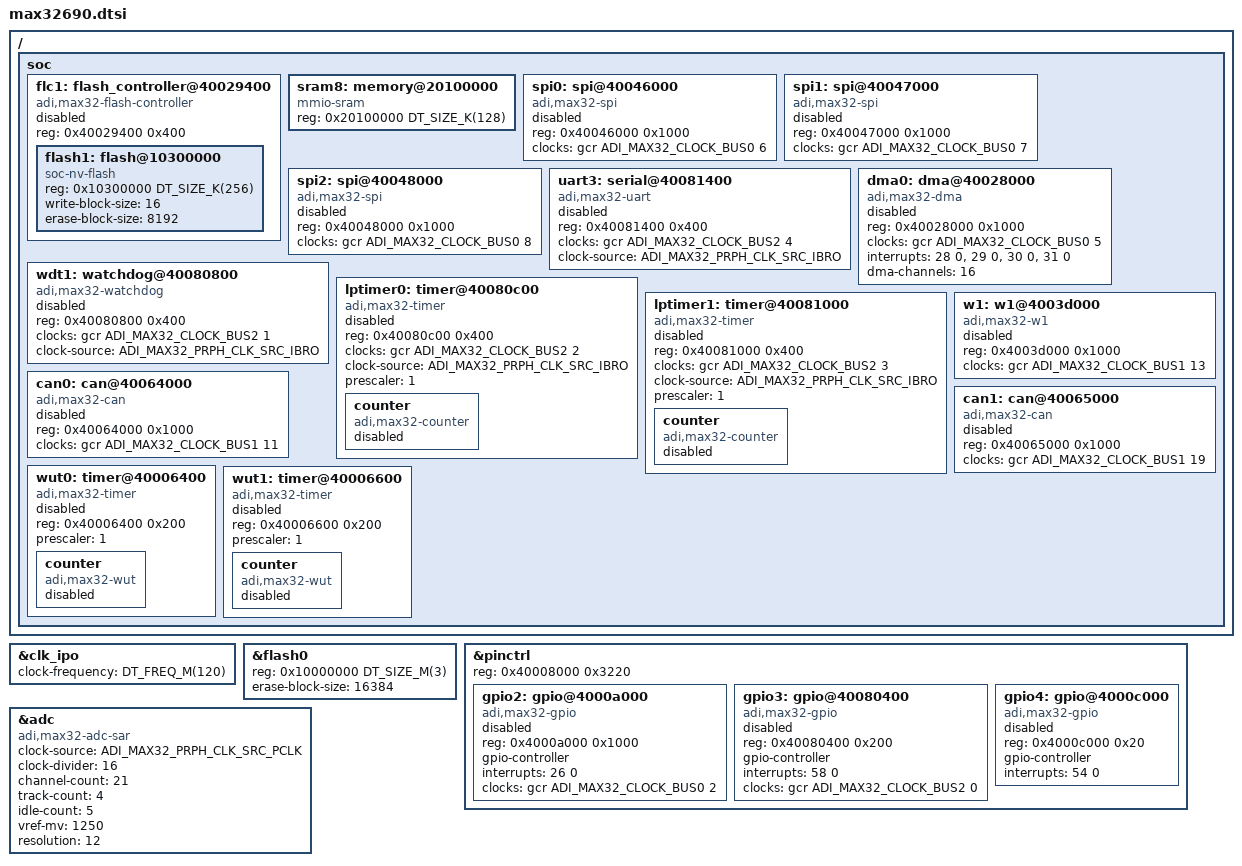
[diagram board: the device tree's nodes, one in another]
/*
 * Copyright (c) 2023-2025 Analog Devices, Inc.
 *
 * SPDX-License-Identifier: Apache-2.0
 */

#include <adi/max32/max32xxx.dtsi>
#include <zephyr/dt-bindings/dma/max32690_dma.h>

&clk_ipo {
	clock-frequency = <DT_FREQ_M(120)>;
};

&flash0 {
	reg = <0x10000000 DT_SIZE_M(3)>;
	ranges = <0x0 0x10000000 DT_SIZE_M(3)>;
	erase-block-size = <16384>;
};

&pinctrl {
	reg = <0x40008000 0x3220>;

	gpio2: gpio@4000a000 {
		reg = <0x4000a000 0x1000>;
		compatible = "adi,max32-gpio";
		gpio-controller;
		#gpio-cells = <2>;
		interrupts = <26 0>;
		clocks = <&gcr ADI_MAX32_CLOCK_BUS0 2>;
		status = "disabled";
	};

	gpio3: gpio@40080400 {
		reg = <0x40080400 0x200>;
		compatible = "adi,max32-gpio";
		gpio-controller;
		#gpio-cells = <2>;
		interrupts = <58 0>;
		clocks = <&gcr ADI_MAX32_CLOCK_BUS2 0>;
		status = "disabled";
	};

	gpio4: gpio@4000c000 {
		reg = <0x4000c000 0x20>;
		compatible = "adi,max32-gpio";
		gpio-controller;
		#gpio-cells = <2>;
		interrupts = <54 0>;
		status = "disabled";
	};
};

&adc {
	compatible = "adi,max32-adc-sar", "adi,max32-adc";
	clock-source = <ADI_MAX32_PRPH_CLK_SRC_PCLK>;
	clock-divider = <16>;
	channel-count = <21>;
	track-count = <4>;
	idle-count = <5>;
	vref-mv = <1250>;
	resolution = <12>;
};

/* MAX32690 extra peripherals. */
/ {
	soc {
		flc1: flash_controller@40029400 {
			compatible = "adi,max32-flash-controller";
			reg = <0x40029400 0x400>;

			#address-cells = <1>;
			#size-cells = <1>;
			status = "disabled";

			flash1: flash@10300000 {
				compatible = "soc-nv-flash";
				reg = <0x10300000 DT_SIZE_K(256)>;
				ranges = <0x0 0x10300000 DT_SIZE_K(256)>;
				#address-cells = <1>;
				#size-cells = <1>;
				write-block-size = <16>;
				erase-block-size = <8192>;
			};
		};

		// SRAM8 is accessible to either core
		sram8: memory@20100000 {
			compatible = "mmio-sram";
			reg = <0x20100000 DT_SIZE_K(128)>;
		};

		spi0: spi@40046000 {
			compatible = "adi,max32-spi";
			reg = <0x40046000 0x1000>;
			#address-cells = <1>;
			#size-cells = <0>;
			clocks = <&gcr ADI_MAX32_CLOCK_BUS0 6>;
			status = "disabled";
		};

		spi1: spi@40047000 {
			compatible = "adi,max32-spi";
			reg = <0x40047000 0x1000>;
			#address-cells = <1>;
			#size-cells = <0>;
			clocks = <&gcr ADI_MAX32_CLOCK_BUS0 7>;
			status = "disabled";
		};

		spi2: spi@40048000 {
			compatible = "adi,max32-spi";
			reg = <0x40048000 0x1000>;
			#address-cells = <1>;
			#size-cells = <0>;
			clocks = <&gcr ADI_MAX32_CLOCK_BUS0 8>;
			status = "disabled";
		};

		uart3: serial@40081400 {
			compatible = "adi,max32-uart";
			reg = <0x40081400 0x400>;
			clocks = <&gcr ADI_MAX32_CLOCK_BUS2 4>;
			clock-source = <ADI_MAX32_PRPH_CLK_SRC_IBRO>;
			status = "disabled";
		};

		dma0: dma@40028000 {
			compatible = "adi,max32-dma";
			reg = <0x40028000 0x1000>;
			clocks = <&gcr ADI_MAX32_CLOCK_BUS0 5>;
			interrupts = <28 0>, <29 0>, <30 0>, <31 0>;
			dma-channels = <16>;
			status = "disabled";
			#dma-cells = <2>;
		};

		wdt1: watchdog@40080800 {
			compatible = "adi,max32-watchdog";
			reg = <0x40080800 0x400>;
			clocks = <&gcr ADI_MAX32_CLOCK_BUS2 1>;
			clock-source = <ADI_MAX32_PRPH_CLK_SRC_IBRO>;
			status = "disabled";
		};

		lptimer0: timer@40080c00 {
			compatible = "adi,max32-timer";
			reg = <0x40080c00 0x400>;
			status = "disabled";
			clocks = <&gcr ADI_MAX32_CLOCK_BUS2 2>;
			clock-source = <ADI_MAX32_PRPH_CLK_SRC_IBRO>;
			prescaler = <1>;

			counter {
				compatible = "adi,max32-counter";
				status = "disabled";
			};
		};

		lptimer1: timer@40081000 {
			compatible = "adi,max32-timer";
			reg = <0x40081000 0x400>;
			status = "disabled";
			clocks = <&gcr ADI_MAX32_CLOCK_BUS2 3>;
			clock-source = <ADI_MAX32_PRPH_CLK_SRC_IBRO>;
			prescaler = <1>;

			counter {
				compatible = "adi,max32-counter";
				status = "disabled";
			};
		};

		w1: w1@4003d000 {
			compatible = "adi,max32-w1";
			reg = <0x4003d000 0x1000>;
			clocks = <&gcr ADI_MAX32_CLOCK_BUS1 13>;
			status = "disabled";
		};

		can0: can@40064000 {
			compatible = "adi,max32-can";
			reg = <0x40064000 0x1000>;
			status = "disabled";
			clocks = <&gcr ADI_MAX32_CLOCK_BUS1 11>;
		};

		can1: can@40065000 {
			compatible = "adi,max32-can";
			reg = <0x40065000 0x1000>;
			status = "disabled";
			clocks = <&gcr ADI_MAX32_CLOCK_BUS1 19>;
		};

		wut0: timer@40006400 {
			compatible = "adi,max32-timer";
			reg = <0x40006400 0x200>;
			status = "disabled";
			prescaler = <1>;

			counter {
				compatible = "adi,max32-wut";
				status = "disabled";
			};
		};

		wut1: timer@40006600 {
			compatible = "adi,max32-timer";
			reg = <0x40006600 0x200>;
			status = "disabled";
			prescaler = <1>;

			counter {
				compatible = "adi,max32-wut";
				status = "disabled";
			};
		};
	};
};
